# PY32F001Cxx register map
Vendor: Puya; Series: PY32F0; File version: 1.0.0
CPU: CM0+ r0p1, little endian, no MPU, no FPU, 4 interrupt priority bits
Registers are 32-bit, read-write, reset 0x0 unless marked. A register's access mark holds for its fields unless they carry their own. Offsets are from the block's base; [hi:lo] are bit positions; {n}, {i} and the like mark numbered series.

## CRC — CRC calculation unit
Base 0x40023000
0x00 DR — Data register
  [31:0] DR — Data Register
0x04 IDR — Independent Data register
  [7:0] IDR
0x08 CR — Control register
  [0] RESET — Reset bit

## DBGMCU — Debug support
Base 0x40015800
0x00 DBG_IDCODE
  [31:0] DBG_ID ro
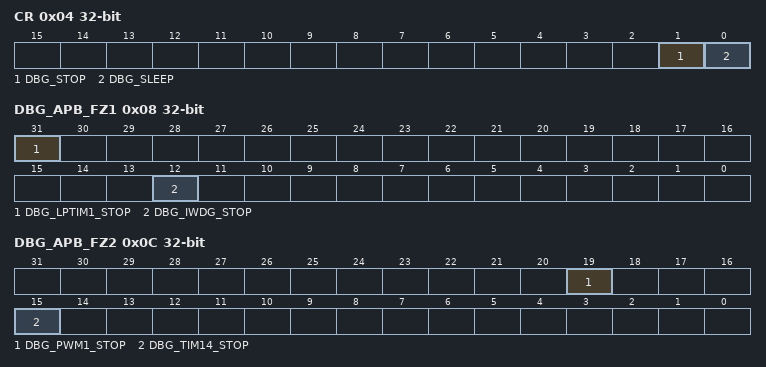
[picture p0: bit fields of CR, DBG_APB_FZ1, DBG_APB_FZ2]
0x04 CR — Debug MCU Configuration Register
  [1] DBG_STOP, [0] DBG_SLEEP
0x08 DBG_APB_FZ1
  [31] DBG_LPTIM1_STOP, [12] DBG_IWDG_STOP
0x0C DBG_APB_FZ2
  [19] DBG_PWM1_STOP, [15] DBG_TIM14_STOP

## EXTI — External interrupt/event controller
Base 0x40021800
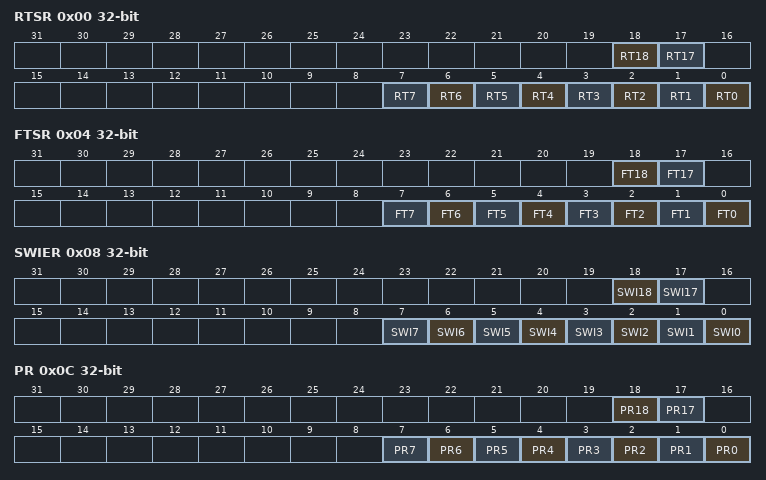
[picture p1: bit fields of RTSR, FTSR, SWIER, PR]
0x00 RTSR — EXTI rising trigger selection register
  [18] RT18 — Rising trigger event configuration bit of Configurable Event input
  [17] RT17 — Rising trigger event configuration bit of Configurable Event input
  [n] RT{n} (n=0..7) — Rising trigger event configuration bit of Configurable Event input
0x04 FTSR — EXTI falling trigger selection register
  [18] FT18 — Falling trigger event configuration bit of Configurable Event input
  [17] FT17 — Falling trigger event configuration bit of Configurable Event input
  [n] FT{n} (n=0..7) — Falling trigger event configuration bit of Configurable Event input
0x08 SWIER — EXTI software interrupt event register
  [18] SWI18 — Rising trigger event configuration bit of Configurable Event input
  [17] SWI17 — Rising trigger event configuration bit of Configurable Event input
  [n] SWI{n} (n=0..7) — Rising trigger event configuration bit of Configurable Event input
0x0C PR — EXTI pending register
  [18] PR18 — configurable event inputs x rising edge Pending bit.
  [17] PR17 — configurable event inputs x rising edge Pending bit.
  [n] PR{n} (n=0..7) — configurable event inputs x rising edge Pending bit.
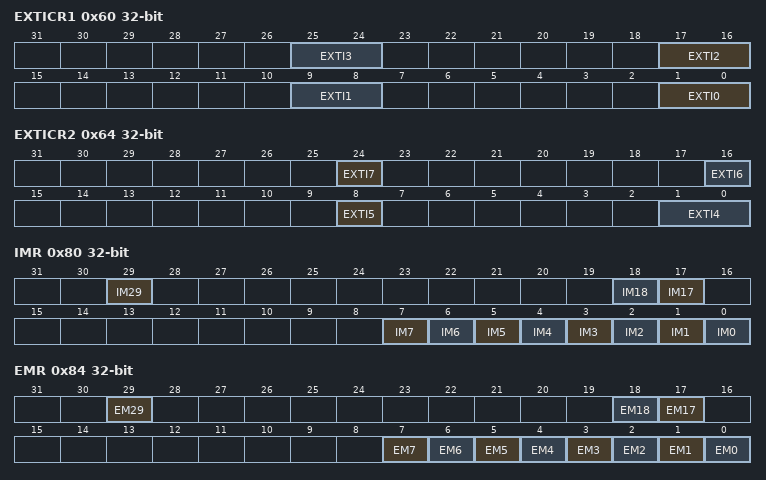
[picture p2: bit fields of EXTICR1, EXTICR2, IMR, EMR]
0x60 EXTICR1 — EXTI external interrupt selection register
  [8n+1:8n] EXTI{n} (n=0..3) — GPIO port selection
0x64 EXTICR2 — EXTI external interrupt selection register
  [24] EXTI7 — GPIO port selection
  [16] EXTI6 — GPIO port selection
  [8] EXTI5 — GPIO port selection
  [1:0] EXTI4 — GPIO port selection
0x80 IMR — EXTI CPU wakeup with interrupt mask register
  [29] IM29 — CPU wakeup with interrupt mask on event input
  [18] IM18 — CPU wakeup with interrupt mask on event input
  [17] IM17 — CPU wakeup with interrupt mask on event input
  [n] IM{n} (n=0..7) — CPU wakeup with interrupt mask on event input
0x84 EMR — EXTI CPU wakeup with event mask register
  [29] EM29 — CPU wakeup with event mask on event input
  [18] EM18 — CPU wakeup with event mask on event input
  [17] EM17 — CPU wakeup with event mask on event input
  [n] EM{n} (n=0..7) — CPU wakeup with event mask on event input

## FLASH
Base 0x40022000
0x08 KEYR — Flash key register
  [31:0] KEY wo — Flash CR key
0x0C OPTKEYR — Option byte key register
  [31:0] OPTKEY wo — Flash Option key
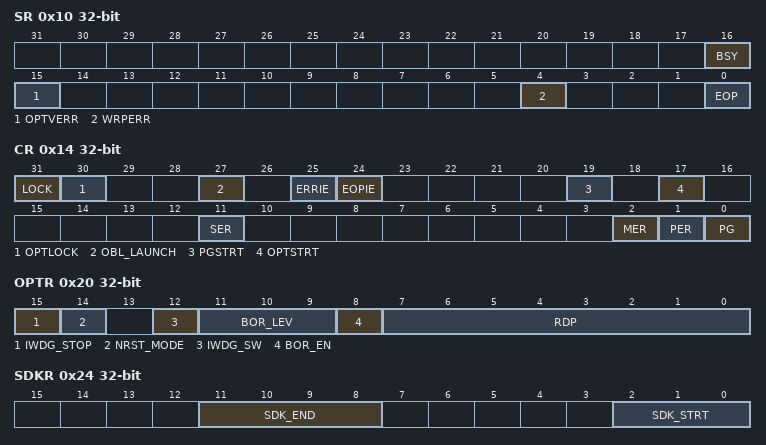
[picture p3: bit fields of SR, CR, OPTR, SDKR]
0x10 SR — Status register
  [16] BSY ro — Busy
  [15] OPTVERR — Option and trimming bits loading validity error
  [4] WRPERR — Write protection error
  [0] EOP — End of operation
0x14 CR — Flash control register
  [31] LOCK
  [30] OPTLOCK — Option Lock
  [27] OBL_LAUNCH — Force the option bytes loading
  [25] ERRIE — Error interrupt enable
  [24] EOPIE — End of operation interrupt enable
  [19] PGSTRT — Programming Start
  [17] OPTSTRT — Option bytes Programming Start
  [11] SER — Sector Erase
  [2] MER — Mass Erase
  [1] PER — Page Erase
  [0] PG — Page Program
0x20 OPTR — Flash option register
  [15] IWDG_STOP — IWDG Software Enable
  [14] NRST_MODE
  [12] IWDG_SW
  [11:9] BOR_LEV
  [8] BOR_EN
  [7:0] RDP — Read Protection
0x24 SDKR — Flash SDK address register
  [11:8] SDK_END, [2:0] SDK_STRT
0x2C WRPR — Flash WRP address register
  [15:0] WRP
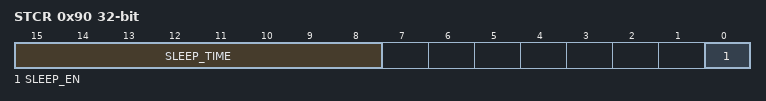
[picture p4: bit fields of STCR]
0x90 STCR — Flash sleep time config register
  [15:8] SLEEP_TIME
  [0] SLEEP_EN — Sleep enable
0x100 TS0 — Flash TS0 register
  [7:0] TS0
0x104 TS1 — Flash TS1 register
  [7:0] TS1
0x108 TS2P — Flash TS2P register
  [7:0] TS2P
0x10C TPS3 — Flash TPS3 register
  [9:0] TPS3
0x110 TS3 — Flash TS3 register
  [7:0] TS3
0x114 ERTPE
  [15:0] ERTPE
0x11C PRGTPE — Flash PRGTPE register
  [15:0] PRGTPE
0x120 PRETPE — Flash PRETPE register
  [13:0] PRETPE
